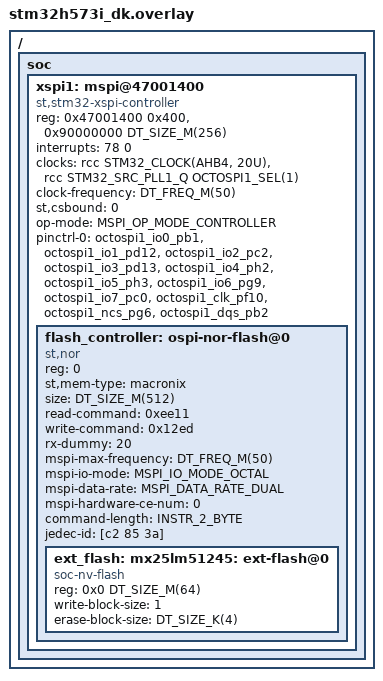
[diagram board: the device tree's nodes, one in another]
/*
 * Copyright (c) 2026 EXALT Technologies
 *
 * SPDX-License-Identifier: Apache-2.0
 */

/* Replace the xspi1 by a "st,stm32-xspi-controller" compatible */
/delete-node/ &xspi1;

/ {
	soc {
		xspi1: mspi@47001400 {
			compatible = "st,stm32-xspi-controller";
			reg = <0x47001400 0x400>, <0x90000000 DT_SIZE_M(256)>;
			interrupts = <78 0>;
			clock-names = "xspix", "xspi-ker";
			clocks = <&rcc STM32_CLOCK(AHB4, 20U)>,
				 <&rcc STM32_SRC_PLL1_Q OCTOSPI1_SEL(1)>;
			clock-frequency = <DT_FREQ_M(50)>;
			#address-cells = <1>;
			#size-cells = <0>;
			st,csbound = <0>;
			op-mode = "MSPI_OP_MODE_CONTROLLER";
			status = "okay";
			pinctrl-0 = <&octospi1_io0_pb1 &octospi1_io1_pd12
				     &octospi1_io2_pc2 &octospi1_io3_pd13
				     &octospi1_io4_ph2 &octospi1_io5_ph3
				     &octospi1_io6_pg9 &octospi1_io7_pc0
				     &octospi1_clk_pf10 &octospi1_ncs_pg6
				     &octospi1_dqs_pb2>;
			pinctrl-names = "default";

			flash_controller: ospi-nor-flash@0 {
				compatible = "st,nor", "mxicy,mx25u", "jedec,nor";
				reg = <0>;
				st,mem-type = "macronix";
				size = <DT_SIZE_M(512)>; /* 512 Mbits */
				status = "okay";
				read-command = <0xee11>;
				write-command = <0x12ed>;
				rx-dummy = <20>;
				mspi-max-frequency = <DT_FREQ_M(50)>;
				mspi-io-mode = "MSPI_IO_MODE_OCTAL";
				mspi-data-rate = "MSPI_DATA_RATE_DUAL";
				mspi-hardware-ce-num = <0>;
				command-length = "INSTR_2_BYTE";
				jedec-id = [c2 85 3a];
				#address-cells = <1>;
				#size-cells = <1>;

				ext_flash: mx25lm51245: ext-flash@0 {
					compatible = "soc-nv-flash";
					reg = <0x0 DT_SIZE_M(64)>;
					write-block-size = <1>;
					erase-block-size = <DT_SIZE_K(4)>;
				};
			};
		};
	};
};
